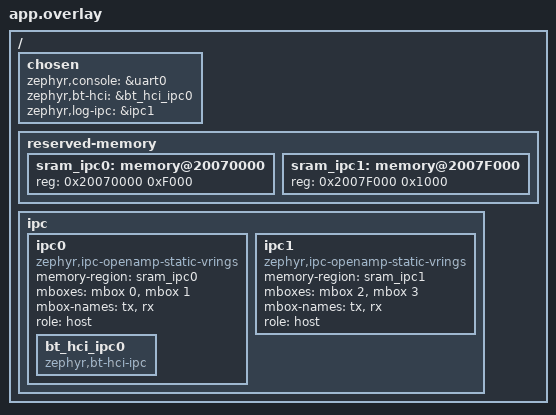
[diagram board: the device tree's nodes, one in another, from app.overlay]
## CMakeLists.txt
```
cmake_minimum_required(VERSION 3.20.0)

find_package(Zephyr REQUIRED HINTS $ENV{ZEPHYR_BASE})

project(multidomain_appcore)

target_sources(app PRIVATE src/main.c)
```

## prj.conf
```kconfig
# Debug Options
CONFIG_MISRA_SANE=n
CONFIG_DEBUG_OPTIMIZATIONS=y
CONFIG_DEBUG_THREAD_INFO=y
CONFIG_INIT_STACKS=y
CONFIG_IPC_SERVICE_LOG_LEVEL_INF=y

# The following zephyr cast results in temporary high stack usage on the thread mounting FATFS.
# While the FATFS structs are static and thus do not take up any space on the stack, C casts
# create a temporary variable and as the FATFS struct is ~4KB this results in high stack usage.
# C:\ncs\vX.X.X\zephyr\subsys\fs\fat_fs.c:451 `f_mount((FATFS *)mountp->fs_data, ...);`
CONFIG_MAIN_STACK_SIZE=8192
CONFIG_SYSTEM_WORKQUEUE_STACK_SIZE=2048

# IPC requires (K_HEAP_MEM_POOL_SIZE > 0)
# C:\ncs\vX.X.X\modules\hal\libmetal\libmetal\lib\system\zephyr\alloc.h
CONFIG_HEAP_MEM_POOL_SIZE=8192

# Netcore Options
CONFIG_SOC_NRF53_CPUNET_ENABLE=y

# Print Options
CONFIG_PRINTK=n
CONFIG_BOOT_BANNER=n
CONFIG_NCS_BOOT_BANNER=n

# Console Options
CONFIG_CONSOLE=n
CONFIG_RTT_CONSOLE=n
CONFIG_UART_CONSOLE=n

# IPC Options
CONFIG_MBOX=y
CONFIG_IPC_SERVICE=y
CONFIG_IPC_SERVICE_BACKEND_RPMSG=y
CONFIG_OPENAMP=y
CONFIG_OPENAMP_MASTER=y
CONFIG_OPENAMP_SLAVE=n

# Logging Options
CONFIG_LOG=y
CONFIG_LOG_OUTPUT=y
CONFIG_LOG_BUFFER_SIZE=8192
CONFIG_LOG_PROCESS_THREAD=y
CONFIG_LOG_PROCESS_THREAD_STACK_SIZE=4096
CONFIG_LOG_PROCESSING_LATENCY_US=100000

# Log Mode Options
CONFIG_LOG_MODE_DEFERRED=y
CONFIG_LOG_MODE_IMMEDIATE=n
CONFIG_LOG_MODE_MINIMAL=n

# Log Multidomain Options
CONFIG_LOG_MULTIDOMAIN=y
CONFIG_LOG_LINK_IPC_SERVICE=y
CONFIG_LOG_BACKEND_IPC_SERVICE=n

# Log Backend Options
CONFIG_LOG_BACKEND_RTT=n
CONFIG_LOG_BACKEND_SWO=n
CONFIG_LOG_BACKEND_UART=n
```

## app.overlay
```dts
#include <zephyr/dt-bindings/ipc_service/static_vrings.h>

/ {
    chosen {
        // ipc-shm is not required for bt-ipc or log-ipc
        /delete-property/ zephyr,ipc_shm;
        zephyr,console = &uart0;
        zephyr,bt-hci = &bt_hci_ipc0;
        zephyr,log-ipc = &ipc1;
    };

    reserved-memory {
        /delete-node/ memory@20070000;

        sram_ipc0: memory@20070000 {
            reg = <0x20070000 0xF000>;
        };

        sram_ipc1: memory@2007F000 {
            reg = <0x2007F000 0x1000>;
        };
    };

    ipc {
        // Override nrf5340 Default IPC Node
        /delete-node/ ipc0;

        ipc0: ipc0 {
            compatible = "zephyr,ipc-openamp-static-vrings";
            memory-region = <&sram_ipc0>;
            mboxes = <&mbox 0>, <&mbox 1>;
            mbox-names = "tx", "rx";
            role = "host";
            status = "okay";

            bt_hci_ipc0: bt_hci_ipc0 {
                compatible = "zephyr,bt-hci-ipc";
                status = "okay";
            };
        };

        ipc1: ipc1 {
            compatible = "zephyr,ipc-openamp-static-vrings";
            memory-region = <&sram_ipc1>;
            mboxes = <&mbox 2>, <&mbox 3>;
            mbox-names = "tx", "rx";
            role = "host";
            status = "okay";
        };
    };
};
```

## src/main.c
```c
#include <zephyr/kernel.h>
#include <zephyr/logging/log.h>
#include <zephyr/sys/printk.h>

LOG_MODULE_REGISTER(multidomain_appcore_main, LOG_LEVEL_DBG);

int main(void)
{
    int cnt = 0;

    while (1)
    {
        LOG_INF("loop: %d", cnt++);
        k_sleep(K_SECONDS(1));
    }
    return 0;
}
```
